# PY32F001Bxx register map
Vendor: Puya; Series: PY32F0; File version: 1.0.0
Arm 32-bit Cortex-M0+ Microcontroller based device, CPU clock up to 48 MHz.
CPU: CM0+ r0p1, little endian, no MPU, no FPU, 4 interrupt priority bits
Registers are 32-bit, read-write, reset 0x0 unless marked. A register's access mark holds for its fields unless they carry their own. Offsets are from the block's base; lines under a group give offsets from that group; [hi:lo] are bit positions; {n}, {i} and the like mark numbered series; 'fields as' and 'values as' point back to an identical list; <NAME> marks a mode.

## Memory map
0x40002400 TIM14 size 0x60
0x40002800 PWM size 0x80
0x40003000 IWDG size 0x400 — Independent watchdog
0x40004800 UART1 size 0x30
0x40007000 PWR size 0x400 — Power control
0x40007C00 LPTIM1 size 0x400 — Low power timer
0x40010000 SYSCFG size 0x30 — System configuration controller
0x40010100 VREF size 0x10
0x40012400 ADC size 0x400 — Analog to Digital Converter
0x40012C00 TIM1 size 0x400 — Advanced timer
0x40015800 DBGMCU size 0x400 — Debug support
0x40021000 RCC size 0x400 — Reset and clock control
0x40021800 EXTI size 0x400 — External interrupt/event controller
0x40022000 FLASH size 0x400
0x50000000 GPIOA size 0x400 — General-purpose I/Os
0x50000400 GPIOB size 0x400
0x50000800 GPIOC size 0x400 — General-purpose I/Os

## Interrupts
3 FLASH — FLASH global Interrupt
4 RCC — RCC global Interrupt
5 EXTI0_1 (EXTI) — EXTI Line 0 and 1 Interrupt
6 EXTI2_3 (EXTI) — EXTI Line 2 and 3 Interrupt
7 EXTI4_15 (EXTI) — EXTI Line 4 to 15 Interrupt
12 ADC_COMP (ADC) — ADC and COMP Interrupts
13 TIM1_BRK_UP_TRG_COM (TIM1) — TIM1 Break, Update, Trigger and Commutation Interrupt
14 TIM1_CC (TIM1) — TIM1 Capture Compare Interrupt
17 LPTIM1_DAC (LPTIM1) — LPTIM1, DAC global Interrupts

## ADC — Analog to Digital Converter
Base 0x40012400
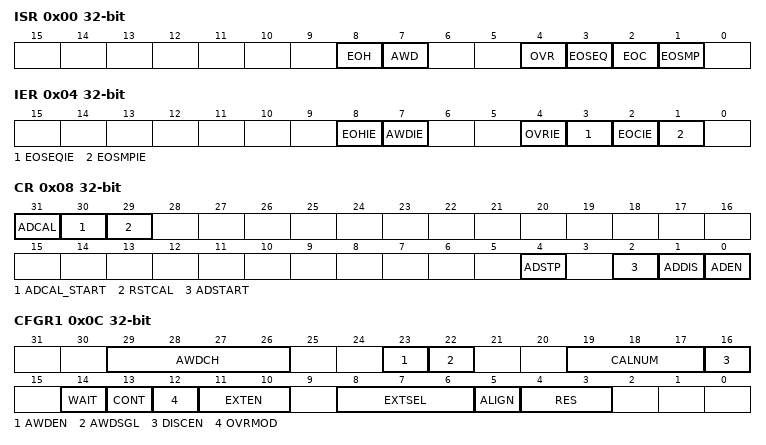
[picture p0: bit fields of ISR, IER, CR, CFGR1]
0x00 ISR — ADC interrupt and status register
  [8] EOH, [7] AWD, [4] OVR, [3] EOSEQ, [2] EOC, [1] EOSMP
0x04 IER — ADC interrupt enable register
  [8] EOHIE, [7] AWDIE, [4] OVRIE, [3] EOSEQIE, [2] EOCIE, [1] EOSMPIE
0x08 CR — ADC control register
  [31] ADCAL, [30] ADCAL_START, [29] RSTCAL, [4] ADSTP, [2] ADSTART, [1] ADDIS, [0] ADEN
0x0C CFGR1
  [29:26] AWDCH, [23] AWDEN, [22] AWDSGL, [19:17] CALNUM, [16] DISCEN, [14] WAIT, [13] CONT, [12] OVRMOD, [11:10] EXTEN, [8:6] EXTSEL, [5] ALIGN, [4:3] RES
0x10 CFGR2 — ADC configuration register 2
  [31:28] CKMODE
0x14 SMPR — ADC sampling time register
  [2:0] SMP
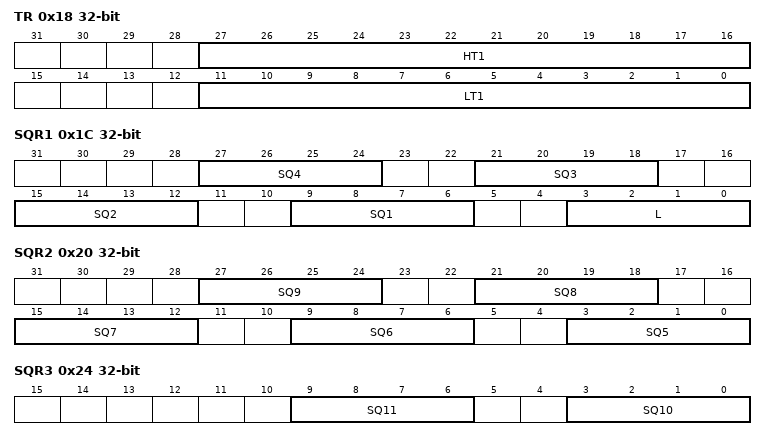
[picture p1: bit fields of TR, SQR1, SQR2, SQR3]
0x18 TR — ADC analog watchdog 1 threshold register
  [27:16] HT1, [11:0] LT1
0x1C SQR1
  [6n+3:6n] SQ{n} (n=1..4), [3:0] L
0x20 SQR2
  [6n-27:6n-30] SQ{n} (n=5..9)
0x24 SQR3
  [9:6] SQ11, [3:0] SQ10
0x28 DR
  [15:0] DATA ro
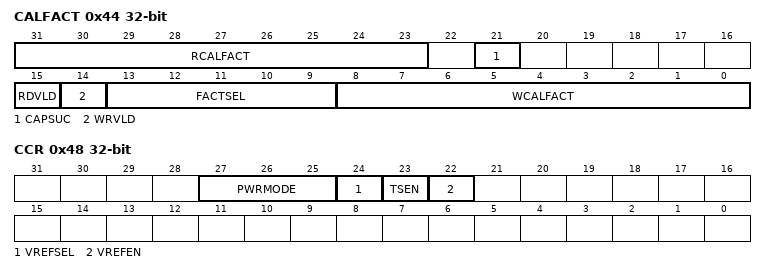
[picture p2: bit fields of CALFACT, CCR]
0x44 CALFACT
  [31:23] RCALFACT ro, [21] CAPSUC, [15] RDVLD, [14] WRVLD, [13:9] FACTSEL, [8:0] WCALFACT
0x48 CCR — ADC common configuration register
  [27:25] PWRMODE, [24] VREFSEL, [23] TSEN, [22] VREFEN

## DBGMCU — Debug support
Base 0x40015800
0x00 DBG_IDCODE
  [31:0] DBG_ID ro
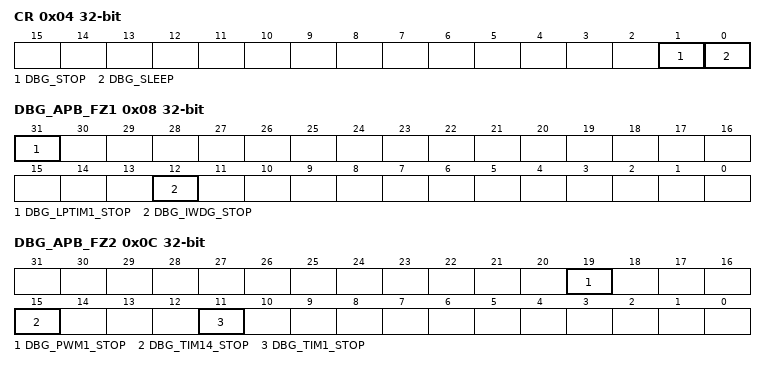
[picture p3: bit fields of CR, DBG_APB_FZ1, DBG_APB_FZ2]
0x04 CR — Debug MCU Configuration Register
  [1] DBG_STOP, [0] DBG_SLEEP
0x08 DBG_APB_FZ1
  [31] DBG_LPTIM1_STOP, [12] DBG_IWDG_STOP
0x0C DBG_APB_FZ2
  [19] DBG_PWM1_STOP, [15] DBG_TIM14_STOP, [11] DBG_TIM1_STOP

## EXTI — External interrupt/event controller
Base 0x40021800
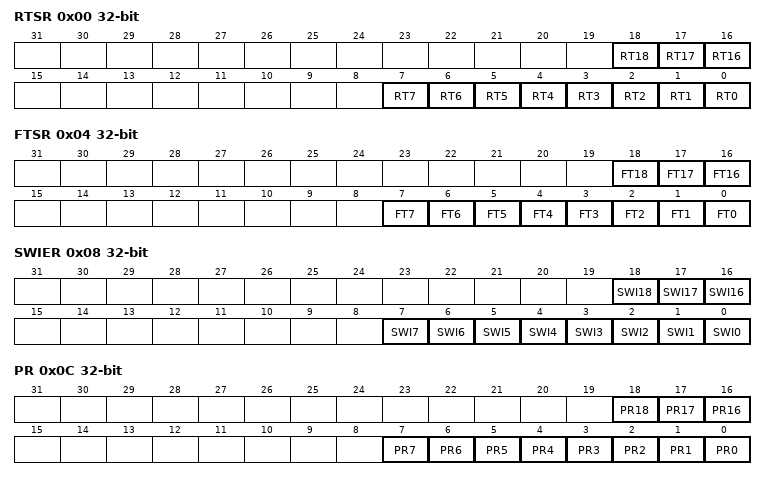
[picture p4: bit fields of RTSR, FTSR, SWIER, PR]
0x00 RTSR — EXTI rising trigger selection register
  [18] RT18 — Rising trigger event configuration bit of Configurable Event input
  [17] RT17 — Rising trigger event configuration bit of Configurable Event input
  [16] RT16 — Rising trigger event configuration bit of Configurable Event input
  [n] RT{n} (n=0..7) — Rising trigger event configuration bit of Configurable Event input
0x04 FTSR — EXTI falling trigger selection register
  [18] FT18 — Falling trigger event configuration bit of Configurable Event input
  [17] FT17 — Falling trigger event configuration bit of Configurable Event input
  [16] FT16 — Falling trigger event configuration bit of Configurable Event input
  [n] FT{n} (n=0..7) — Falling trigger event configuration bit of Configurable Event input
0x08 SWIER — EXTI software interrupt event register
  [18] SWI18 — Rising trigger event configuration bit of Configurable Event input
  [17] SWI17 — Rising trigger event configuration bit of Configurable Event input
  [16] SWI16 — Rising trigger event configuration bit of Configurable Event input
  [n] SWI{n} (n=0..7) — Rising trigger event configuration bit of Configurable Event input
0x0C PR — EXTI pending register
  [18] PR18 — configurable event inputs x rising edge Pending bit.
  [17] PR17 — configurable event inputs x rising edge Pending bit.
  [16] PR16 — configurable event inputs x rising edge Pending bit.
  [n] PR{n} (n=0..7) — configurable event inputs x rising edge Pending bit.
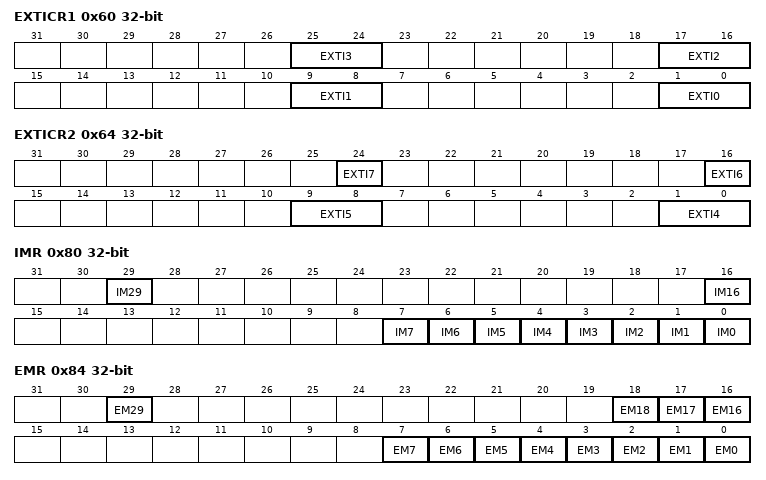
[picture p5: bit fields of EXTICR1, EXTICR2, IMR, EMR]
0x60 EXTICR1 — EXTI external interrupt selection register
  [8n+1:8n] EXTI{n} (n=0..3) — GPIO port selection
0x64 EXTICR2 — EXTI external interrupt selection register
  [24] EXTI7 — GPIO port selection
  [16] EXTI6 — GPIO port selection
  [9:8] EXTI5 — GPIO port selection
  [1:0] EXTI4 — GPIO port selection
0x80 IMR — EXTI CPU wakeup with interrupt mask register
  [29] IM29 — CPU wakeup with interrupt mask on event input
  [16] IM16 — CPU wakeup with interrupt mask on event input
  [n] IM{n} (n=0..7) — CPU wakeup with interrupt mask on event input
0x84 EMR — EXTI CPU wakeup with event mask register
  [29] EM29 — CPU wakeup with event mask on event input
  [18] EM18 — CPU wakeup with event mask on event input
  [17] EM17 — CPU wakeup with event mask on event input
  [16] EM16 — CPU wakeup with event mask on event input
  [n] EM{n} (n=0..7) — CPU wakeup with event mask on event input
